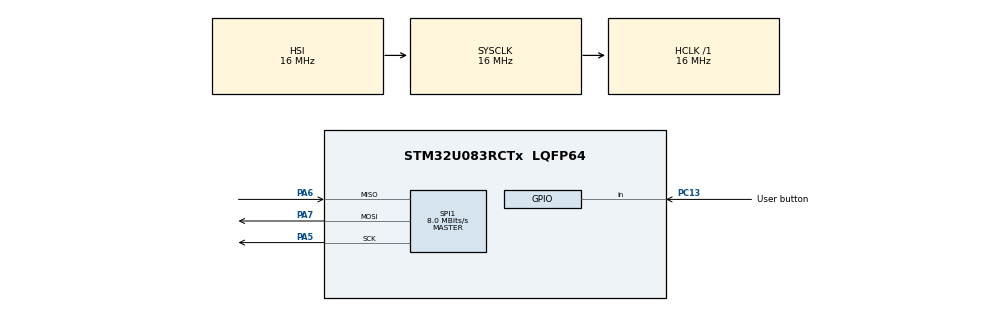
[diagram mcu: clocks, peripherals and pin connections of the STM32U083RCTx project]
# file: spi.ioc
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Mcu.Family=STM32U0
Mcu.Name=STM32U083RCTx
Mcu.Package=LQFP64
NVIC.PriorityGroup=NVIC_PRIORITYGROUP_2
NVIC.SPI1_IRQn=true\:0\:0\:false\:false\:true\:true\:true\:true
PA13\ (SWDIO).GPIO_Label=SWDIO
PA13\ (SWDIO).Signal=DEBUG_JTMS-SWDIO
PA14\ (SWCLK).GPIO_Label=SWCLK
PA14\ (SWCLK).Signal=DEBUG_JTCK-SWCLK
PA2.GPIO_Label=USART2_TX
PA2.Signal=USART2_TX
PA3.GPIO_Label=USART2_RX
PA3.Signal=USART2_RX
PA5.Mode=Full_Duplex_Master
PA5.Signal=SPI1_SCK
PA6.Mode=Full_Duplex_Master
PA6.Signal=SPI1_MISO
PA7.Mode=Full_Duplex_Master
PA7.Signal=SPI1_MOSI
PB8.GPIO_Label=I2C1_SCL
PB8.Signal=I2C1_SCL
PB9.GPIO_Label=I2C1_SDA
PB9.Signal=I2C1_SDA
PC13.GPIO_Label=User button
PC13.Signal=GPIO_Input
PC14-OSC32_IN.GPIO_Label=OSC32_IN
PC14-OSC32_IN.Signal=RCC_OSC32_IN
PC15-OSC32_OUT.GPIO_Label=OSC32_OUT
PC15-OSC32_OUT.Signal=RCC_OSC32_OUT
PF0-OSC_IN.GPIO_Label=OSC_IN
PF0-OSC_IN.Mode=HSE-External-Oscillator
PF0-OSC_IN.Signal=RCC_OSC_IN
PF1-OSC_OUT.GPIO_Label=OSC_OUT
PF1-OSC_OUT.Mode=HSE-External-Oscillator
PF1-OSC_OUT.Signal=RCC_OSC_OUT
ProjectManager.HeapSize=0x200
ProjectManager.StackSize=0x400
ProjectManager.TargetToolchain=STM32CubeIDE
RCC.AHBFreq_Value=16000000
RCC.CortexFreq_Value=16000000
RCC.HCLKFreq_Value=16000000
RCC.HSE_VALUE=4000000
RCC.HSI48_VALUE=48000000
RCC.HSI_VALUE=16000000
RCC.LSE_VALUE=32768
RCC.MSI_VALUE=4000000
RCC.SYSCLKFreq_VALUE=16000000
RCC.VCOOutputFreq_Value=64000000
SPI1.BaudRatePrescaler=SPI_BAUDRATEPRESCALER_2
SPI1.CalculateBaudRate=8.0 MBits/s
SPI1.DataSize=SPI_DATASIZE_8BIT
SPI1.Direction=SPI_DIRECTION_2LINES
SPI1.Mode=SPI_MODE_MASTER
SPI1.VirtualType=VM_MASTER
VP_PWR_VS_SECSignals.Mode=Security/Privilege
board=NUCLEO-U083RC

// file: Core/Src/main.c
/* USER CODE BEGIN Header */
/**
  ******************************************************************************
  * @file           : main.c
  * @brief          : Main program body
  ******************************************************************************
  * @attention
  *
  * Copyright (c) 2026 STMicroelectronics.
  * All rights reserved.
  *
  * This software is licensed under terms that can be found in the LICENSE file
  * in the root directory of this software component.
  * If no LICENSE file comes with this software, it is provided AS-IS.
  *
  ******************************************************************************
  */
/* USER CODE END Header */
#include "main.h"

SPI_HandleTypeDef hspi1;

/* USER CODE BEGIN PV */
uint8_t tx_cmd;
uint8_t rx_data;
/* USER CODE END PV */

void SystemClock_Config(void);
static void MX_GPIO_Init(void);
static void MX_SPI1_Init(void);

int main(void)
{

  /* MCU Configuration--------------------------------------------------------*/

  /* Reset of all peripherals, Initializes the Flash interface and the Systick. */
  HAL_Init();

  /* Configure the system clock */
  SystemClock_Config();

  /* Initialize all configured peripherals */
  MX_GPIO_Init();
  MX_SPI1_Init();

  /* Infinite loop */
  while (1)
  {

    /* USER CODE BEGIN 3 */
	tx_cmd = 0x48;
	rx_data = 0;
	// transmit and wait for slave answer 100ms
	HAL_StatusTypeDef status = HAL_SPI_TransmitReceive(&hspi1, &tx_cmd, &rx_data, 1, 100);
	HAL_Delay(1000);
  }
  /* USER CODE END 3 */
}

void SystemClock_Config(void)
{
  RCC_OscInitTypeDef RCC_OscInitStruct = {0};
  RCC_ClkInitTypeDef RCC_ClkInitStruct = {0};

  /** Configure the main internal regulator output voltage
  */
  HAL_PWREx_ControlVoltageScaling(PWR_REGULATOR_VOLTAGE_SCALE2);

  /** Initializes the RCC Oscillators according to the specified parameters
  * in the RCC_OscInitTypeDef structure.
  */
  RCC_OscInitStruct.OscillatorType = RCC_OSCILLATORTYPE_HSI;
  RCC_OscInitStruct.HSIState = RCC_HSI_ON;
  RCC_OscInitStruct.HSICalibrationValue = RCC_HSICALIBRATION_DEFAULT;
  RCC_OscInitStruct.PLL.PLLState = RCC_PLL_NONE;
  if (HAL_RCC_OscConfig(&RCC_OscInitStruct) != HAL_OK)
  {
    Error_Handler();
  }

  /** Initializes the CPU, AHB and APB buses clocks
  */
  RCC_ClkInitStruct.ClockType = RCC_CLOCKTYPE_HCLK|RCC_CLOCKTYPE_SYSCLK
                              |RCC_CLOCKTYPE_PCLK1;
  RCC_ClkInitStruct.SYSCLKSource = RCC_SYSCLKSOURCE_HSI;
  RCC_ClkInitStruct.AHBCLKDivider = RCC_SYSCLK_DIV1;
  RCC_ClkInitStruct.APB1CLKDivider = RCC_HCLK_DIV1;

  if (HAL_RCC_ClockConfig(&RCC_ClkInitStruct, FLASH_LATENCY_1) != HAL_OK)
  {
    Error_Handler();
  }
}

static void MX_SPI1_Init(void)
{

  /* SPI1 parameter configuration*/
  hspi1.Instance = SPI1;
  hspi1.Init.Mode = SPI_MODE_MASTER;
  hspi1.Init.Direction = SPI_DIRECTION_2LINES;
  hspi1.Init.DataSize = SPI_DATASIZE_8BIT;
  hspi1.Init.CLKPolarity = SPI_POLARITY_LOW;
  hspi1.Init.CLKPhase = SPI_PHASE_1EDGE;
  hspi1.Init.NSS = SPI_NSS_SOFT;
  hspi1.Init.BaudRatePrescaler = SPI_BAUDRATEPRESCALER_2;
  hspi1.Init.FirstBit = SPI_FIRSTBIT_MSB;
  hspi1.Init.TIMode = SPI_TIMODE_DISABLE;
  hspi1.Init.CRCCalculation = SPI_CRCCALCULATION_DISABLE;
  hspi1.Init.CRCPolynomial = 7;
  hspi1.Init.CRCLength = SPI_CRC_LENGTH_DATASIZE;
  hspi1.Init.NSSPMode = SPI_NSS_PULSE_ENABLE;
  if (HAL_SPI_Init(&hspi1) != HAL_OK)
  {
    Error_Handler();
  }

}

static void MX_GPIO_Init(void)
{
  GPIO_InitTypeDef GPIO_InitStruct = {0};

  /* GPIO Ports Clock Enable */
  __HAL_RCC_GPIOC_CLK_ENABLE();
  __HAL_RCC_GPIOF_CLK_ENABLE();
  __HAL_RCC_GPIOA_CLK_ENABLE();
  __HAL_RCC_GPIOB_CLK_ENABLE();

  /*Configure GPIO pin : User_button_Pin */
  GPIO_InitStruct.Pin = User_button_Pin;
  GPIO_InitStruct.Mode = GPIO_MODE_INPUT;
  GPIO_InitStruct.Pull = GPIO_NOPULL;
  HAL_GPIO_Init(User_button_GPIO_Port, &GPIO_InitStruct);

  /*Configure GPIO pins : USART2_TX_Pin USART2_RX_Pin */
  GPIO_InitStruct.Pin = USART2_TX_Pin|USART2_RX_Pin;
  GPIO_InitStruct.Mode = GPIO_MODE_AF_PP;
  GPIO_InitStruct.Pull = GPIO_NOPULL;
  GPIO_InitStruct.Speed = GPIO_SPEED_FREQ_LOW;
  GPIO_InitStruct.Alternate = GPIO_AF7_USART2;
  HAL_GPIO_Init(GPIOA, &GPIO_InitStruct);

  /*Configure GPIO pins : I2C1_SCL_Pin I2C1_SDA_Pin */
  GPIO_InitStruct.Pin = I2C1_SCL_Pin|I2C1_SDA_Pin;
  GPIO_InitStruct.Mode = GPIO_MODE_AF_OD;
  GPIO_InitStruct.Pull = GPIO_NOPULL;
  GPIO_InitStruct.Speed = GPIO_SPEED_FREQ_LOW;
  GPIO_InitStruct.Alternate = GPIO_AF4_I2C1;
  HAL_GPIO_Init(GPIOB, &GPIO_InitStruct);

}

void Error_Handler(void)
{
  __disable_irq();
  while (1)
  {
  }
}
